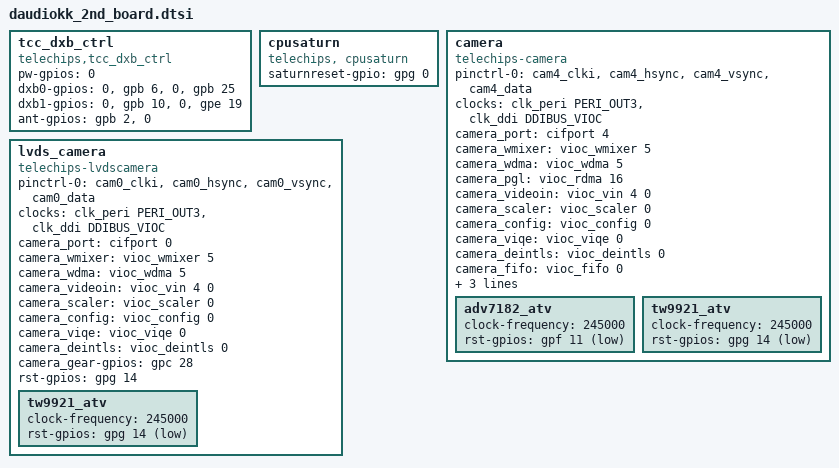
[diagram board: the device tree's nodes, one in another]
	tcc_dxb_ctrl {
		compatible = "telechips,tcc_dxb_ctrl";
		/* DAUDIO BEGIN */
		/*
		pw-gpios   = <&gpext2 27 0>;
		dxb0-gpios = <&gpext2 30 0>, <&gpext2 28 0>, <&gpe 8 0>, <&gpe 1 0>;
		dxb1-gpios = <&gpext2 31 0>, <&gpext2 29 0>, <&gpe 9 0>, <&gpe 17 0>;
		ant-gpios  = <0>, <0>;
		*/
		pw-gpios   = <0>;
		dxb0-gpios = <0>, <&gpb 6 0>, <0>, <&gpb 25 0>;
		dxb1-gpios = <0>, <&gpb 10 0>, <0>, <&gpe 19 0>;
		ant-gpios  = <&gpb 2 0>, <0>;
		/* DAUDIO END */
	};


	/* DAUDIO BEGIN */
	//CPU Saturn reset
	cpusaturn {
		compatible = "telechips, cpusaturn";
		saturnreset-gpio = <&gpg 0 0>; 
	};

	camera {
		compatible = "telechips-camera";
		status = "okay";
		pinctrl-names = "default";
		pinctrl-0 = <&cam4_clki &cam4_hsync &cam4_vsync &cam4_data>;
		clocks = <&clk_peri PERI_OUT3 &clk_ddi DDIBUS_VIOC>;
		camera_port = <&cifport 4>;
		camera_wmixer = <&vioc_wmixer 5>;
		camera_wdma = <&vioc_wdma 5>;
		camera_pgl = <&vioc_rdma 16>;
		camera_videoin = <&vioc_vin 4 0>;
		camera_scaler = <&vioc_scaler 0>;
		camera_config = <&vioc_config 0>;
		camera_viqe = <&vioc_viqe 0>;
		camera_deintls = <&vioc_deintls 0>;
		camera_fifo = <&vioc_fifo 0>;
		camera_gear-gpios = <&gpc 28 0>;
		camera_viqe_set = <&viqe_hidden>;
		rst-gpios = <&gpg 14 0>;

		// support image sensor module list
/*
		mt9p111_5mp{
			clock-frequency = <240000>;
			rst-gpios = <&gpext2 19 0>;
			pwr-gpios = <&gpext2 18 1>;
			pwd-gpios = <&gpc 22 1>;
		};
		mt9m113_1_3mp{
			clock-frequency = <240000>;
			rst-gpios = <&gpext2 20 0>;
			pwr-gpios = <&gpext2 18 1>;
			pwd-gpios = <&gpext2 21 1>;
		};
		s5k5caga_3mp{
			clock-frequency = <240000>;
			rst-gpios = <&gpext2 19 0>;
			pwr-gpios = <&gpext2 18 1>;
			pwd-gpios = <&gpc 22 1>;
		};
		sr130pc10_1_3mp{
			clock-frequency = <240000>;
			rst-gpios = <&gpext2 20 0>;
			pwr-gpios = <&gpext2 18 1>;
			pwd-gpios = <&gpext2 21 1>;
		};
		mt9t111_3mp{
			clock-frequency = <240000>;
			rst-gpios = <&gpext2 19 0>;
			pwr-gpios = <&gpext2 18 1>;
			pwd-gpios = <&gpc 22 1>;
		};
		mt9t113_3mp{
			clock-frequency = <247500>;
			rst-gpios = <&gpext2 19 0>;
			pwr-gpios = <&gpext2 18 1>;
			pwd-gpios = <&gpc 22 1>;
		};
		mt9d112_2mp{
			clock-frequency = <240000>;
			rst-gpios = <&gpext2 19 0>;
			pwr-gpios = <&gpext2 18 1>;
			pwd-gpios = <&gpc 22 1>;
		};
		ov7690_vga{
			clock-frequency = <240000>;
			rst-gpios = <&gpext2 20 0>;
			pwr-gpios = <&gpext2 18 1>;
			pwd-gpios = <&gpext2 21 1>;
		};
		siv100b_vga{
			clock-frequency = <240000>;
			rst-gpios = <&gpext2 20 0>;
			pwr-gpios = <&gpext2 18 1>;
			pwd-gpios = <&gpext2 21 1>;
		};
		tvp5150_atv{
			clock-frequency = <245000>;
			rst-gpios = <&gpext2 20 1>;
			pwr-gpios = <&gpext2 18 1>;
			pwd-gpios = <&gpext2 21 1>;
		};
*/
		adv7182_atv{
			clock-frequency = <245000>;
			rst-gpios = <&gpf 11 1>;
		};
		/* DAUDIO BEGIN */
		
		tw9921_atv{      //mhjung change
			clock-frequency = <245000>;
			rst-gpios = <&gpg 14 1>;
		};
		/* DAUDIO END */
	};
	lvds_camera {
		compatible = "telechips-lvdscamera";
		status = "okay";
		pinctrl-names = "default";
        	pinctrl-0 = <&cam0_clki &cam0_hsync &cam0_vsync &cam0_data>;
        	clocks = <&clk_peri PERI_OUT3 &clk_ddi DDIBUS_VIOC>;
		camera_port = <&cifport 0>;
		camera_wmixer = <&vioc_wmixer 5>;
		camera_wdma = <&vioc_wdma 5>;
		camera_videoin = <&vioc_vin 4 0>;
		camera_scaler = <&vioc_scaler 0>;
		camera_config = <&vioc_config 0>;
		camera_viqe = <&vioc_viqe 0>;
		camera_deintls = <&vioc_deintls 0>;
		camera_gear-gpios = <&gpc 28 0>;
		rst-gpios = <&gpg 14 0>;
		
		tw9921_atv{      //mhjung change
			clock-frequency = <245000>;
			rst-gpios = <&gpg 14 1>;
		};
		
	};

